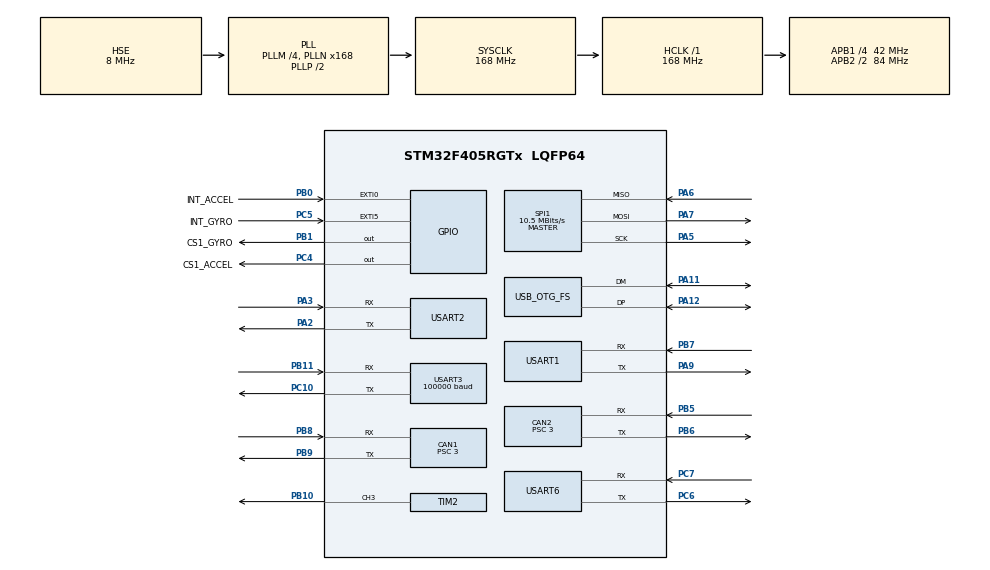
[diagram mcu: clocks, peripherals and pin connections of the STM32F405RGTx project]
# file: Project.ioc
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CAN1.ABOM=ENABLE
CAN1.AWUM=ENABLE
CAN1.BS1=CAN_BS1_10TQ
CAN1.BS2=CAN_BS2_3TQ
CAN1.CalculateBaudRate=1000000
CAN1.CalculateTimeBit=1000
CAN1.CalculateTimeQuantum=71.42857142857143
CAN1.Prescaler=3
CAN2.ABOM=ENABLE
CAN2.AWUM=ENABLE
CAN2.BS1=CAN_BS1_10TQ
CAN2.BS2=CAN_BS2_3TQ
CAN2.CalculateBaudRate=1000000
CAN2.CalculateTimeBit=1000
CAN2.CalculateTimeQuantum=71.42857142857143
CAN2.Prescaler=3
Dma.Request0=USART1_RX
Dma.Request1=USART1_TX
Dma.Request2=USART2_RX
Dma.Request3=USART2_TX
Dma.Request4=USART3_RX
Dma.Request5=USART6_RX
Dma.Request6=USART6_TX
Dma.USART1_RX.0.Direction=DMA_PERIPH_TO_MEMORY
Dma.USART1_RX.0.FIFOMode=DMA_FIFOMODE_DISABLE
Dma.USART1_RX.0.Instance=DMA2_Stream2
Dma.USART1_RX.0.MemDataAlignment=DMA_MDATAALIGN_BYTE
Dma.USART1_RX.0.MemInc=DMA_MINC_ENABLE
Dma.USART1_RX.0.Mode=DMA_CIRCULAR
Dma.USART1_RX.0.PeriphDataAlignment=DMA_PDATAALIGN_BYTE
Dma.USART1_RX.0.PeriphInc=DMA_PINC_DISABLE
Dma.USART1_RX.0.Priority=DMA_PRIORITY_HIGH
Dma.USART1_TX.1.Direction=DMA_MEMORY_TO_PERIPH
Dma.USART1_TX.1.FIFOMode=DMA_FIFOMODE_DISABLE
Dma.USART1_TX.1.Instance=DMA2_Stream7
Dma.USART1_TX.1.MemDataAlignment=DMA_MDATAALIGN_BYTE
Dma.USART1_TX.1.MemInc=DMA_MINC_ENABLE
Dma.USART1_TX.1.Mode=DMA_NORMAL
Dma.USART1_TX.1.PeriphDataAlignment=DMA_PDATAALIGN_BYTE
Dma.USART1_TX.1.PeriphInc=DMA_PINC_DISABLE
Dma.USART1_TX.1.Priority=DMA_PRIORITY_HIGH
Dma.USART2_RX.2.Direction=DMA_PERIPH_TO_MEMORY
Dma.USART2_RX.2.FIFOMode=DMA_FIFOMODE_DISABLE
Dma.USART2_RX.2.Instance=DMA1_Stream5
Dma.USART2_RX.2.MemDataAlignment=DMA_MDATAALIGN_BYTE
Dma.USART2_RX.2.MemInc=DMA_MINC_ENABLE
Dma.USART2_RX.2.Mode=DMA_NORMAL
Dma.USART2_RX.2.PeriphDataAlignment=DMA_PDATAALIGN_BYTE
Dma.USART2_RX.2.PeriphInc=DMA_PINC_DISABLE
Dma.USART2_RX.2.Priority=DMA_PRIORITY_MEDIUM
Dma.USART2_TX.3.Direction=DMA_MEMORY_TO_PERIPH
Dma.USART2_TX.3.FIFOMode=DMA_FIFOMODE_DISABLE
Dma.USART2_TX.3.Instance=DMA1_Stream6
Dma.USART2_TX.3.MemDataAlignment=DMA_MDATAALIGN_BYTE
Dma.USART2_TX.3.MemInc=DMA_MINC_ENABLE
Dma.USART2_TX.3.Mode=DMA_NORMAL
Dma.USART2_TX.3.PeriphDataAlignment=DMA_PDATAALIGN_BYTE
Dma.USART2_TX.3.PeriphInc=DMA_PINC_DISABLE
Dma.USART2_TX.3.Priority=DMA_PRIORITY_MEDIUM
Dma.USART3_RX.4.Direction=DMA_PERIPH_TO_MEMORY
Dma.USART3_RX.4.FIFOMode=DMA_FIFOMODE_DISABLE
Dma.USART3_RX.4.Instance=DMA1_Stream1
Dma.USART3_RX.4.MemDataAlignment=DMA_MDATAALIGN_BYTE
Dma.USART3_RX.4.MemInc=DMA_MINC_ENABLE
Dma.USART3_RX.4.Mode=DMA_CIRCULAR
Dma.USART3_RX.4.PeriphDataAlignment=DMA_PDATAALIGN_BYTE
Dma.USART3_RX.4.PeriphInc=DMA_PINC_DISABLE
Dma.USART3_RX.4.Priority=DMA_PRIORITY_HIGH
Dma.USART6_RX.5.Direction=DMA_PERIPH_TO_MEMORY
Dma.USART6_RX.5.FIFOMode=DMA_FIFOMODE_DISABLE
Dma.USART6_RX.5.Instance=DMA2_Stream1
Dma.USART6_RX.5.MemDataAlignment=DMA_MDATAALIGN_BYTE
Dma.USART6_RX.5.MemInc=DMA_MINC_ENABLE
Dma.USART6_RX.5.Mode=DMA_CIRCULAR
Dma.USART6_RX.5.PeriphDataAlignment=DMA_PDATAALIGN_BYTE
Dma.USART6_RX.5.PeriphInc=DMA_PINC_DISABLE
Dma.USART6_RX.5.Priority=DMA_PRIORITY_VERY_HIGH
Dma.USART6_TX.6.Direction=DMA_MEMORY_TO_PERIPH
Dma.USART6_TX.6.FIFOMode=DMA_FIFOMODE_DISABLE
Dma.USART6_TX.6.Instance=DMA2_Stream6
Dma.USART6_TX.6.MemDataAlignment=DMA_MDATAALIGN_BYTE
Dma.USART6_TX.6.MemInc=DMA_MINC_ENABLE
Dma.USART6_TX.6.Mode=DMA_NORMAL
Dma.USART6_TX.6.PeriphDataAlignment=DMA_PDATAALIGN_BYTE
Dma.USART6_TX.6.PeriphInc=DMA_PINC_DISABLE
Dma.USART6_TX.6.Priority=DMA_PRIORITY_VERY_HIGH
FREERTOS.Tasks01=defaultTask,0,128,StartDefaultTask,Default,NULL,Dynamic,NULL,NULL;MainLoop,2,512,MainLoop_Task,As external,NULL,Dynamic,NULL,NULL;MotorLoop,0,512,MotorLoop_Task,As external,NULL,Dynamic,NULL,NULL;StateLoop,-2,512,StateLoop_Task,As external,NULL,Dynamic,NULL,NULL
Mcu.Family=STM32F4
Mcu.Name=STM32F405RGTx
Mcu.Package=LQFP64
NVIC.CAN1_RX0_IRQn=true\:5\:0\:false\:false\:true\:true\:true\:true\:true
NVIC.CAN1_RX1_IRQn=true\:5\:0\:false\:false\:true\:true\:true\:true\:true
NVIC.CAN2_RX0_IRQn=true\:5\:0\:false\:false\:true\:true\:true\:true\:true
NVIC.CAN2_RX1_IRQn=true\:5\:0\:false\:false\:true\:true\:true\:true\:true
NVIC.DMA1_Stream1_IRQn=true\:5\:0\:false\:false\:true\:true\:false\:true\:true
NVIC.DMA1_Stream5_IRQn=true\:5\:0\:false\:false\:true\:true\:false\:true\:true
NVIC.DMA1_Stream6_IRQn=true\:5\:0\:false\:false\:true\:true\:false\:true\:true
NVIC.DMA2_Stream1_IRQn=true\:5\:0\:false\:false\:true\:true\:false\:true\:true
NVIC.DMA2_Stream2_IRQn=true\:5\:0\:false\:false\:true\:true\:false\:true\:true
NVIC.DMA2_Stream6_IRQn=true\:5\:0\:false\:false\:true\:true\:false\:true\:true
NVIC.DMA2_Stream7_IRQn=true\:5\:0\:false\:false\:true\:true\:false\:true\:true
NVIC.OTG_FS_IRQn=true\:5\:0\:false\:false\:true\:true\:false\:true\:true
NVIC.PriorityGroup=NVIC_PRIORITYGROUP_4
NVIC.TIM7_IRQn=true\:15\:0\:false\:false\:true\:false\:false\:true\:true
NVIC.TimeBase=TIM7_IRQn
NVIC.TimeBaseIP=TIM7
NVIC.USART1_IRQn=true\:5\:0\:false\:false\:true\:true\:true\:true\:true
NVIC.USART2_IRQn=true\:5\:0\:false\:false\:true\:true\:true\:true\:true
NVIC.USART3_IRQn=true\:5\:0\:false\:false\:true\:true\:true\:true\:true
NVIC.USART6_IRQn=true\:5\:0\:false\:false\:true\:true\:true\:true\:true
PA11.Mode=Device_Only
PA11.Signal=USB_OTG_FS_DM
PA12.Mode=Device_Only
PA12.Signal=USB_OTG_FS_DP
PA13.Mode=Serial_Wire
PA13.Signal=SYS_JTMS-SWDIO
PA14.Mode=Serial_Wire
PA14.Signal=SYS_JTCK-SWCLK
PA2.Mode=Asynchronous
PA2.Signal=USART2_TX
PA3.Mode=Asynchronous
PA3.Signal=USART2_RX
PA5.Mode=Full_Duplex_Master
PA5.Signal=SPI1_SCK
PA6.Mode=Full_Duplex_Master
PA6.Signal=SPI1_MISO
PA7.Mode=Full_Duplex_Master
PA7.Signal=SPI1_MOSI
PA9.Mode=Asynchronous
PA9.Signal=USART1_TX
PB0.GPIO_Label=INT_ACCEL
PB0.Signal=GPXTI0
PB1.GPIO_Label=CS1_GYRO
PB1.GPIO_PuPd=GPIO_PULLUP
PB1.GPIO_Speed=GPIO_SPEED_FREQ_HIGH
PB1.PinState=GPIO_PIN_SET
PB1.Signal=GPIO_Output
PB10.Signal=S_TIM2_CH3
PB11.Mode=Asynchronous
PB11.Signal=USART3_RX
PB5.Mode=CAN_Activate
PB5.Signal=CAN2_RX
PB6.Mode=CAN_Activate
PB6.Signal=CAN2_TX
PB7.Mode=Asynchronous
PB7.Signal=USART1_RX
PB8.Mode=CAN_Activate
PB8.Signal=CAN1_RX
PB9.Mode=CAN_Activate
PB9.Signal=CAN1_TX
PC10.Mode=Asynchronous
PC10.Signal=USART3_TX
PC4.GPIO_Label=CS1_ACCEL
PC4.GPIO_ModeDefaultOutputPP=GPIO_MODE_OUTPUT_PP
PC4.GPIO_PuPd=GPIO_PULLUP
PC4.GPIO_Speed=GPIO_SPEED_FREQ_HIGH
PC4.PinState=GPIO_PIN_SET
PC4.Signal=GPIO_Output
PC5.GPIO_Label=INT_GYRO
PC5.Signal=GPXTI5
PC6.Mode=Asynchronous
PC6.Signal=USART6_TX
PC7.Mode=Asynchronous
PC7.Signal=USART6_RX
PH0-OSC_IN.Mode=HSE-External-Oscillator
PH0-OSC_IN.Signal=RCC_OSC_IN
PH1-OSC_OUT.Mode=HSE-External-Oscillator
PH1-OSC_OUT.Signal=RCC_OSC_OUT
ProjectManager.HeapSize=0x4000
ProjectManager.StackSize=0x4000
ProjectManager.TargetToolchain=CMake
RCC.48MHZClocksFreq_Value=48000000
RCC.AHBFreq_Value=168000000
RCC.APB1CLKDivider=RCC_HCLK_DIV4
RCC.APB1Freq_Value=42000000
RCC.APB1TimFreq_Value=84000000
RCC.APB2CLKDivider=RCC_HCLK_DIV2
RCC.APB2Freq_Value=84000000
RCC.APB2TimFreq_Value=168000000
RCC.CortexFreq_Value=168000000
RCC.HCLKFreq_Value=168000000
RCC.HSE_VALUE=8000000
RCC.HSI_VALUE=16000000
RCC.LSE_VALUE=32768
RCC.PLLM=4
RCC.PLLN=168
RCC.PLLQ=7
RCC.SYSCLKFreq_VALUE=168000000
RCC.SYSCLKSource=RCC_SYSCLKSOURCE_PLLCLK
RCC.VCOOutputFreq_Value=336000000
SH.S_TIM2_CH3.0=TIM2_CH3,PWM Generation3 CH3
SPI1.BaudRatePrescaler=SPI_BAUDRATEPRESCALER_8
SPI1.CLKPhase=SPI_PHASE_2EDGE
SPI1.CLKPolarity=SPI_POLARITY_HIGH
SPI1.CalculateBaudRate=10.5 MBits/s
SPI1.Direction=SPI_DIRECTION_2LINES
SPI1.Mode=SPI_MODE_MASTER
SPI1.VirtualType=VM_MASTER
STMicroelectronics.X-CUBE-ALGOBUILD.1.4.0.LibraryCcDSPOoLibraryJjDSPOoLibrary=true
TIM2.Channel-PWM\ Generation3\ CH3=TIM_CHANNEL_3
USART1.VirtualMode=VM_ASYNC
USART2.VirtualMode=VM_ASYNC
USART3.BaudRate=100000
USART3.Parity=PARITY_EVEN
USART3.VirtualMode=VM_ASYNC
USART6.VirtualMode=VM_ASYNC
USB_DEVICE.CLASS_NAME_FS=CDC
USB_DEVICE.VirtualMode-CDC_FS=Cdc
USB_DEVICE.VirtualModeFS=Cdc_FS
USB_OTG_FS.VirtualMode=Device_Only
VP_FREERTOS_VS_CMSIS_V1.Mode=CMSIS_V1
VP_STMicroelectronics.X-CUBE-ALGOBUILD_VS_DSPOoLibraryJjLibrary_1.4.0_1.4.0.Mode=DSPOoLibraryJjLibrary
VP_SYS_VS_tim7.Mode=TIM7
VP_USB_DEVICE_VS_USB_DEVICE_CDC_FS.Mode=CDC_FS
board=custom

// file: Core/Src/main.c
/* USER CODE BEGIN Header */
/**
  ******************************************************************************
  * @file           : main.c
  * @brief          : Main program body
  ******************************************************************************
  * @attention
  *
  * Copyright (c) 2025 STMicroelectronics.
  * All rights reserved.
  *
  * This software is licensed under terms that can be found in the LICENSE file
  * in the root directory of this software component.
  * If no LICENSE file comes with this software, it is provided AS-IS.
  *
  ******************************************************************************
  */
/* USER CODE END Header */
#include "main.h"
#include "cmsis_os.h"
#include "can.h"
#include "dma.h"
#include "spi.h"
#include "tim.h"
#include "usart.h"
#include "usb_device.h"
#include "gpio.h"

void SystemClock_Config(void);
void MX_FREERTOS_Init(void);

int main(void)
{

  /* MCU Configuration--------------------------------------------------------*/

  /* Reset of all peripherals, Initializes the Flash interface and the Systick. */
  HAL_Init();

  /* Configure the system clock */
  SystemClock_Config();

  /* Initialize all configured peripherals */
  MX_GPIO_Init();
  MX_DMA_Init();
  MX_CAN1_Init();
  MX_CAN2_Init();
  MX_SPI1_Init();
  MX_TIM2_Init();
  MX_USART1_UART_Init();
  MX_USART2_UART_Init();
  MX_USART3_UART_Init();
  MX_USART6_UART_Init();

  /* Call init function for freertos objects (in cmsis_os2.c) */
  MX_FREERTOS_Init();

  /* Start scheduler */
  osKernelStart();

  /* We should never get here as control is now taken by the scheduler */

  /* Infinite loop */
  while (1)
  {

  }
}

void SystemClock_Config(void)
{
  RCC_OscInitTypeDef RCC_OscInitStruct = {0};
  RCC_ClkInitTypeDef RCC_ClkInitStruct = {0};

  /** Configure the main internal regulator output voltage
  */
  __HAL_RCC_PWR_CLK_ENABLE();
  __HAL_PWR_VOLTAGESCALING_CONFIG(PWR_REGULATOR_VOLTAGE_SCALE1);

  /** Initializes the RCC Oscillators according to the specified parameters
  * in the RCC_OscInitTypeDef structure.
  */
  RCC_OscInitStruct.OscillatorType = RCC_OSCILLATORTYPE_HSE;
  RCC_OscInitStruct.HSEState = RCC_HSE_ON;
  RCC_OscInitStruct.PLL.PLLState = RCC_PLL_ON;
  RCC_OscInitStruct.PLL.PLLSource = RCC_PLLSOURCE_HSE;
  RCC_OscInitStruct.PLL.PLLM = 4;
  RCC_OscInitStruct.PLL.PLLN = 168;
  RCC_OscInitStruct.PLL.PLLP = RCC_PLLP_DIV2;
  RCC_OscInitStruct.PLL.PLLQ = 7;
  if (HAL_RCC_OscConfig(&RCC_OscInitStruct) != HAL_OK)
  {
    Error_Handler();
  }

  /** Initializes the CPU, AHB and APB buses clocks
  */
  RCC_ClkInitStruct.ClockType = RCC_CLOCKTYPE_HCLK|RCC_CLOCKTYPE_SYSCLK
                              |RCC_CLOCKTYPE_PCLK1|RCC_CLOCKTYPE_PCLK2;
  RCC_ClkInitStruct.SYSCLKSource = RCC_SYSCLKSOURCE_PLLCLK;
  RCC_ClkInitStruct.AHBCLKDivider = RCC_SYSCLK_DIV1;
  RCC_ClkInitStruct.APB1CLKDivider = RCC_HCLK_DIV4;
  RCC_ClkInitStruct.APB2CLKDivider = RCC_HCLK_DIV2;

  if (HAL_RCC_ClockConfig(&RCC_ClkInitStruct, FLASH_LATENCY_5) != HAL_OK)
  {
    Error_Handler();
  }
}

void HAL_TIM_PeriodElapsedCallback(TIM_HandleTypeDef *htim)
{
  if (htim->Instance == TIM7)
  {
    HAL_IncTick();
  }
}

void Error_Handler(void)
{
  __disable_irq();
  while (1)
  {
  }
}

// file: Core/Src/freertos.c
/* USER CODE BEGIN Header */
/**
  ******************************************************************************
  * File Name          : freertos.c
  * Description        : Code for freertos applications
  ******************************************************************************
  * @attention
  *
  * Copyright (c) 2025 STMicroelectronics.
  * All rights reserved.
  *
  * This software is licensed under terms that can be found in the LICENSE file
  * in the root directory of this software component.
  * If no LICENSE file comes with this software, it is provided AS-IS.
  *
  ******************************************************************************
  */
/* USER CODE END Header */

#include "FreeRTOS.h"
#include "task.h"
#include "main.h"
#include "cmsis_os.h"

/* USER CODE BEGIN Includes */

#include "main_task.hpp"

/* USER CODE END Includes */

osThreadId defaultTaskHandle;
osThreadId MainLoopHandle;
osThreadId MotorLoopHandle;
osThreadId StateLoopHandle;

void StartDefaultTask(void const * argument);
extern void MainLoop_Task(void const * argument);
extern void MotorLoop_Task(void const * argument);
extern void StateLoop_Task(void const * argument);

extern void MX_USB_DEVICE_Init(void);
void MX_FREERTOS_Init(void); /* (MISRA C 2004 rule 8.1) */

/* GetIdleTaskMemory prototype (linked to static allocation support) */
void vApplicationGetIdleTaskMemory( StaticTask_t **ppxIdleTaskTCBBuffer, StackType_t **ppxIdleTaskStackBuffer, uint32_t *pulIdleTaskStackSize );

/* USER CODE BEGIN GET_IDLE_TASK_MEMORY */
static StaticTask_t xIdleTaskTCBBuffer;
static StackType_t xIdleStack[configMINIMAL_STACK_SIZE];

void vApplicationGetIdleTaskMemory( StaticTask_t **ppxIdleTaskTCBBuffer, StackType_t **ppxIdleTaskStackBuffer, uint32_t *pulIdleTaskStackSize )
{
  *ppxIdleTaskTCBBuffer = &xIdleTaskTCBBuffer;
  *ppxIdleTaskStackBuffer = &xIdleStack[0];
  *pulIdleTaskStackSize = configMINIMAL_STACK_SIZE;
  /* place for user code */
}
/* USER CODE END GET_IDLE_TASK_MEMORY */

void MX_FREERTOS_Init(void) {
  /* USER CODE BEGIN Init */

  MainTask_Init();

  /* USER CODE END Init */

  /* Create the thread(s) */
  /* definition and creation of defaultTask */
  osThreadDef(defaultTask, StartDefaultTask, osPriorityNormal, 0, 128);
  defaultTaskHandle = osThreadCreate(osThread(defaultTask), NULL);

  /* definition and creation of MainLoop */
  osThreadDef(MainLoop, MainLoop_Task, osPriorityHigh, 0, 512);
  MainLoopHandle = osThreadCreate(osThread(MainLoop), NULL);

  /* definition and creation of MotorLoop */
  osThreadDef(MotorLoop, MotorLoop_Task, osPriorityNormal, 0, 512);
  MotorLoopHandle = osThreadCreate(osThread(MotorLoop), NULL);

  /* definition and creation of StateLoop */
  osThreadDef(StateLoop, StateLoop_Task, osPriorityLow, 0, 512);
  StateLoopHandle = osThreadCreate(osThread(StateLoop), NULL);

}

void StartDefaultTask(void const * argument)
{
  /* init code for USB_DEVICE */
  MX_USB_DEVICE_Init();
  for(;;)
  {
    osDelay(1);
  }
}
